# npck3m7k register map
Registers are 8-bit, read-write, no defined reset value unless marked. A register's access mark holds for its fields unless they carry their own. Offsets are from the block's base; [hi:lo] are bit positions; {n}, {i} and the like mark numbered series.

## GPIO0 — GENERAL-PURPOSE I/O
Base 0x40081000
0x00 P0DOUT
0x01 P0DIN
0x02 P0DIR
0x03 P0PULL
0x04 P0PUD
0x05 P0ENVDD
0x06 P0OTYPE

## GPIO1 — GENERAL-PURPOSE I/O
Base 0x40083000
0x00 P1DOUT
0x01 P1DIN
0x02 P1DIR
0x03 P1PULL
0x04 P1PUD
0x05 P1ENVDD
0x06 P1OTYPE

## GPIO2 — GENERAL-PURPOSE I/O
Base 0x40085000
0x00 P2DOUT
0x01 P2DIN
0x02 P2DIR
0x03 P2PULL
0x04 P2PUD
0x05 P2ENVDD
0x06 P2OTYPE

## GPIO3 — GENERAL-PURPOSE I/O
Base 0x40087000
0x00 P3DOUT
0x01 P3DIN
0x02 P3DIR
0x03 P3PULL
0x04 P3PUD
0x05 P3ENVDD
0x06 P3OTYPE

## GPIO4 — GENERAL-PURPOSE I/O
Base 0x40089000
0x00 P4DOUT
0x01 P4DIN
0x02 P4DIR
0x03 P4PULL
0x04 P4PUD
0x05 P4ENVDD
0x06 P4OTYPE

## GPIO5 — GENERAL-PURPOSE I/O
Base 0x4008B000
0x00 P5DOUT
0x01 P5DIN
0x02 P5DIR
0x03 P5PULL
0x04 P5PUD
0x05 P5ENVDD
0x06 P5OTYPE

## GPIO6 — GENERAL-PURPOSE I/O
Base 0x4008D000
0x00 P6DOUT
0x01 P6DIN
0x02 P6DIR
0x03 P6PULL
0x04 P6PUD
0x05 P6ENVDD
0x06 P6OTYPE

## GPIO7 — GENERAL-PURPOSE I/O
Base 0x4008F000
0x00 P7DOUT
0x01 P7DIN
0x02 P7DIR
0x03 P7PULL
0x04 P7PUD
0x05 P7ENVDD
0x06 P7OTYPE

## GPIO8 — GENERAL-PURPOSE I/O
Base 0x40091000
0x00 P8DOUT
0x01 P8DIN
0x02 P8DIR
0x03 P8PULL
0x04 P8PUD
0x05 P8ENVDD
0x06 P8OTYPE

## GPIO9 — GENERAL-PURPOSE I/O
Base 0x40093000
0x00 P9DOUT
0x01 P9DIN
0x02 P9DIR
0x03 P9PULL
0x04 P9PUD
0x05 P9ENVDD
0x06 P9OTYPE

## GPIOA — GENERAL-PURPOSE I/O
Base 0x40095000
0x00 PADOUT
0x01 PADIN
0x02 PADIR
0x03 PAPULL
0x04 PAPUD
0x05 PAENVDD
0x06 PAOTYPE

## GPIOB — GENERAL-PURPOSE I/O
Base 0x40097000
Same registers: GPIOC 0x40099000, GPIOD 0x4009B000, GPIOE 0x4009D000, GPIOF 0x4009F000, GPIOG 0x400A7000, GPIOH 0x400A9000, GPIO_STBY_0 0x400AB000, GPIO_STBY_1 0x400AD000
0x00 PBDOUT
0x01 PBDIN
0x02 PBDIR
0x03 PBPULL
0x04 PBPUD
0x05 PBENVDD
0x06 PBOTYPE

## SMB1 — SMBus-Interface 1
Base 0x40003000
Same registers: SMB2 0x40004000, SMB3 0x40005000, SMB4 0x40006000, SMB5 0x40007000, SMB6 0x40008000
0x00 SMBnSDA
  [7:0] SMB_DAT
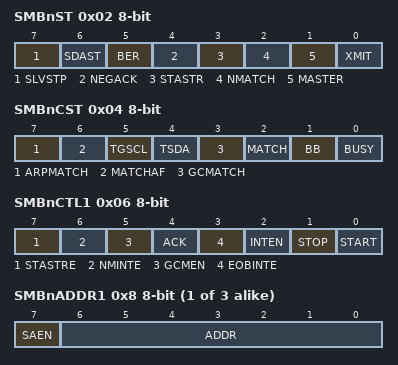
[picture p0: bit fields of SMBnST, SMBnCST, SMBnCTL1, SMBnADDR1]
0x02 SMBnST
  [7] SLVSTP, [6] SDAST, [5] BER, [4] NEGACK, [3] STASTR, [2] NMATCH, [1] MASTER, [0] XMIT
0x04 SMBnCST
  [7] ARPMATCH, [6] MATCHAF, [5] TGSCL, [4] TSDA, [3] GCMATCH, [2] MATCH, [1] BB, [0] BUSY
0x06 SMBnCTL1
  [7] STASTRE, [6] NMINTE, [5] GCMEN, [4] ACK, [3] EOBINTE, [2] INTEN, [1] STOP, [0] START
{0x4+4i} SMBnADDR{i} (i=1..3)
  [7] SAEN, [6:0] ADDR
0x09 TIMEOUT_ST
  [0] T_OUTST
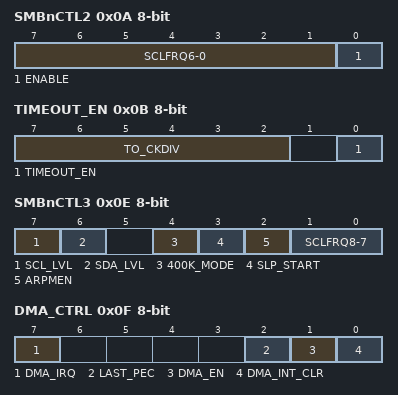
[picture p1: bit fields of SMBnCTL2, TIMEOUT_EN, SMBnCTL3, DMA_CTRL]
0x0A SMBnCTL2
  [7:1] SCLFRQ6-0, [0] ENABLE
0x0B TIMEOUT_EN
  [7:2] TO_CKDIV, [0] TIMEOUT_EN
0x0E SMBnCTL3
  [7] SCL_LVL, [6] SDA_LVL, [4] 400K_MODE, [3] SLP_START, [2] ARPMEN, [1:0] SCLFRQ8-7
0x0F DMA_CTRL
  [7] DMA_IRQ, [2] LAST_PEC, [1] DMA_EN, [0] DMA_INT_CLR
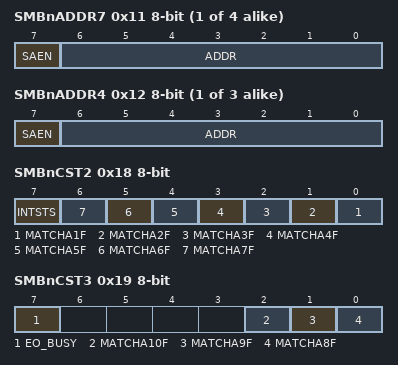
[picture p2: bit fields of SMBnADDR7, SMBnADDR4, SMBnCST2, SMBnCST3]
{0x3+2i} SMBnADDR{i} (i=7..10)
  [7] SAEN, [6:0] ADDR
{0xA+2i} SMBnADDR{i} (i=4..6)
  [7] SAEN, [6:0] ADDR
0x18 SMBnCST2
  [7] INTSTS, [n-1] MATCHA{n}F (n=1..7)
0x19 SMBnCST3
  [7] EO_BUSY, [2] MATCHA10F, [1] MATCHA9F, [0] MATCHA8F
0x1A SMBnCTL4
  [5:0] HLDT
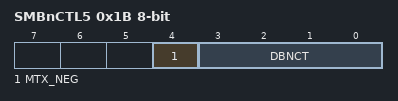
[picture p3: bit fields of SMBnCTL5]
0x1B SMBnCTL5
  [4] MTX_NEG, [3:0] DBNCT
0x1C SMBnSCLLT
  [7:0] SCLLT7-0
0x1E SMBnSCLHT
  [7:0] SCLHT7-0
{0x1F+i} DMA_ADDR{i} (i=1..4)
0x24 DMA_DATA_LEN1
  [7:0] DATA_LEN1
0x25 DMA_DATA_LEN2
  [7:0] DATA_LEN2
0x26 DMA_DATA_CNT1
  [7:0] DATA_CNT1
0x27 DMA_DATA_CNT2
  [7:0] DATA_CNT2
0x29 TIMEOUT_CTL1
0x2A TIMEOUT_CTL2
0x2B SMBnPEC
  [7:0] PEC_DATA

## PS2
Base 0x400B1000
0x00 PSDAT
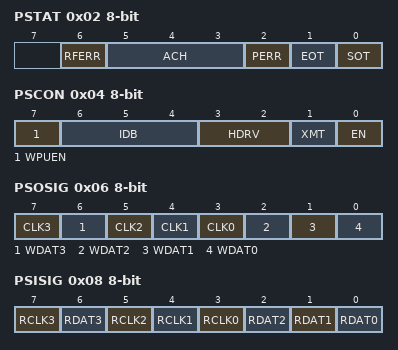
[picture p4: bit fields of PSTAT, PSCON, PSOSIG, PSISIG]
0x02 PSTAT
  [6] RFERR, [5:3] ACH, [2] PERR, [1] EOT, [0] SOT
0x04 PSCON
  [7] WPUEN, [6:4] IDB, [3:2] HDRV, [1] XMT, [0] EN
0x06 PSOSIG
  [7] CLK3, [6] WDAT3, [5] CLK2, [4] CLK1, [3] CLK0, [2] WDAT2, [1] WDAT1, [0] WDAT0
0x08 PSISIG
  [7] RCLK3, [6] RDAT3, [5] RCLK2, [4] RCLK1, [3] RCLK0, [2] RDAT2, [1] RDAT1, [0] RDAT0
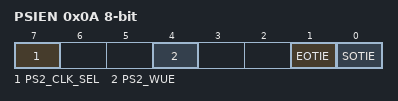
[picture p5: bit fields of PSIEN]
0x0A PSIEN
  [7] PS2_CLK_SEL, [4] PS2_WUE, [1] EOTIE, [0] SOTIE
0x0E PS2_VER
